VERSION ""

NS_ :

BS_:
BU_: XXX

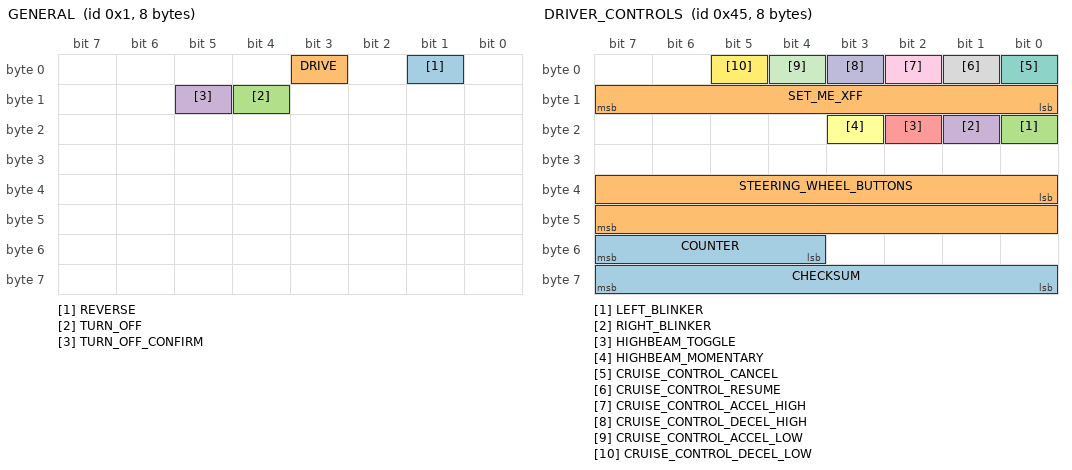
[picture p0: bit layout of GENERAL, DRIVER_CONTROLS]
BO_ 1 GENERAL: 8 XXX
   SG_ REVERSE : 1|1@1+ (1,0) [0|15] "" XXX
   SG_ DRIVE : 3|1@1+ (1,0) [0|15] "" XXX
   SG_ TURN_OFF : 12|1@1+ (1,0) [0|15] "" XXX
   SG_ TURN_OFF_CONFIRM : 13|1@1+ (1,0) [0|15] "" XXX

BO_ 69 DRIVER_CONTROLS: 8 XXX
   SG_ COUNTER : 55|4@0+ (1,0) [0|15] "" XXX
   SG_ STEERING_WHEEL_BUTTONS : 32|16@1+ (1,0) [0|255] "4 directional, 2 volume control & 2 phone buttons" XXX
   SG_ LEFT_BLINKER : 16|1@0+ (1,0) [0|1] "" XXX
   SG_ RIGHT_BLINKER : 17|1@0+ (1,0) [0|1] "" XXX
   SG_ HIGHBEAM_TOGGLE : 18|1@0+ (1,0) [0|1] "" XXX
   SG_ HIGHBEAM_MOMENTARY : 19|1@0+ (1,0) [0|1] "" XXX
   SG_ CRUISE_CONTROL_CANCEL : 0|1@0+ (1,0) [0|1] "" XXX
   SG_ CRUISE_CONTROL_RESUME : 1|1@0+ (1,0) [0|1] "" XXX
   SG_ CRUISE_CONTROL_ACCEL_HIGH : 2|1@0+ (1,0) [0|1] "" XXX
   SG_ CRUISE_CONTROL_DECEL_HIGH : 3|1@0+ (1,0) [0|1] "" XXX
   SG_ CRUISE_CONTROL_ACCEL_LOW : 4|1@0+ (1,0) [0|1] "" XXX
   SG_ CRUISE_CONTROL_DECEL_LOW : 5|1@0+ (1,0) [0|1] "" XXX
   SG_ CHECKSUM : 63|8@0+ (1,0) [0|255] "" XXX
   SG_ SET_ME_XFF : 15|8@0+ (1,0) [0|255] "" XXX

BO_ 115 GEAR_PACKET: 8 XXX
   SG_ GEAR : 0|4@1+ (1,0) [0|15] "" XXX

BO_ 261 GAS_PEDAL: 8 XXX
   SG_ ENGINE_RPM : 6|15@0+ (1,0) [0|255] "rev per X" XXX
   SG_ KICK_DOWN : 7|1@0+ (1,0) [0|1] "" XXX
   SG_ COMBINED_GAS : 32|8@0+ (1,0) [0|255] "" XXX
   SG_ GAS_PEDAL : 40|8@0+ (1,0) [0|255] "" XXX
   SG_ COUNTER : 55|4@0+ (1,0) [0|15] "" XXX
   SG_ CHECKSUM : 63|8@0+ (1,0) [0|255] "" XXX

BO_ 415 UNKNOWN_SPEEDS: 8 XXX
   SG_ WHEEL_SPEED_FL : 2|11@0+ (0.0375,0) [0|255] "mph" XXX

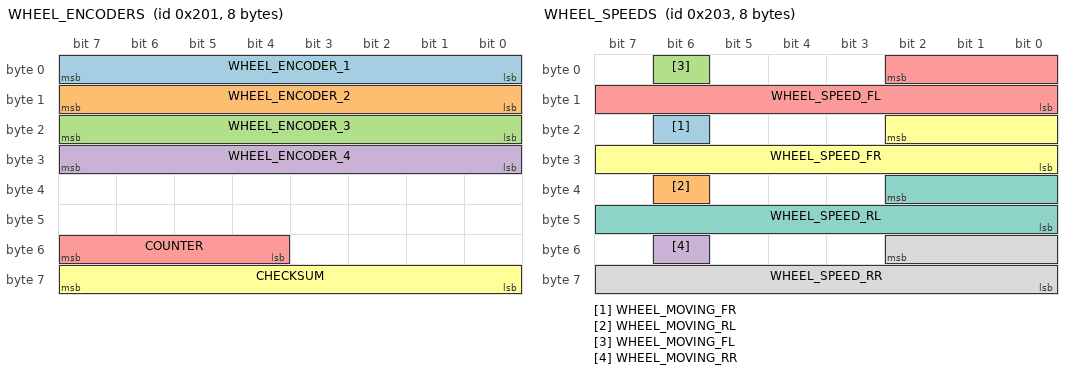
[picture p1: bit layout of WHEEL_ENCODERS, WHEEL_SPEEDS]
BO_ 513 WHEEL_ENCODERS: 8 XXX
   SG_ WHEEL_ENCODER_1 : 7|8@0+ (1,0) [0|255] "" XXX
   SG_ WHEEL_ENCODER_2 : 15|8@0+ (1,0) [0|255] "" XXX
   SG_ WHEEL_ENCODER_3 : 23|8@0+ (1,0) [0|255] "" XXX
   SG_ WHEEL_ENCODER_4 : 31|8@0+ (1,0) [0|255] "" XXX
   SG_ COUNTER : 55|4@0+ (1,0) [0|15] "" XXX
   SG_ CHECKSUM : 56|8@1+ (1,0) [0|255] "" XXX

BO_ 515 WHEEL_SPEEDS: 8 XXX
   SG_ WHEEL_MOVING_FR : 22|1@1+ (1,0) [0|15] "" XXX
   SG_ WHEEL_MOVING_RL : 38|1@0+ (1,0) [0|1] "" XXX
   SG_ WHEEL_MOVING_FL : 6|1@0+ (1,0) [0|1] "" XXX
   SG_ WHEEL_MOVING_RR : 54|1@0+ (1,0) [0|1] "" XXX
   SG_ WHEEL_SPEED_FL : 2|11@0+ (0.0375,0) [0|255] "mph" XXX
   SG_ WHEEL_SPEED_FR : 18|11@0+ (0.0375,0) [0|255] "mph" XXX
   SG_ WHEEL_SPEED_RL : 34|11@0+ (0.0375,0) [0|255] "mph" XXX
   SG_ WHEEL_SPEED_RR : 50|11@0+ (0.0375,0) [0|255] "mph" XXX

BO_ 517 AUX_BAT_VOLTAGE: 8 XXX
   SG_ BAT_12V : 8|8@1+ (0.1,0) [0|255] "V" XXX

BO_ 581 IGNITION: 8 XXX
   SG_ STEERING_WHEEL : 1|15@0- (0.01,0) [-5000|5000] "x" XXX

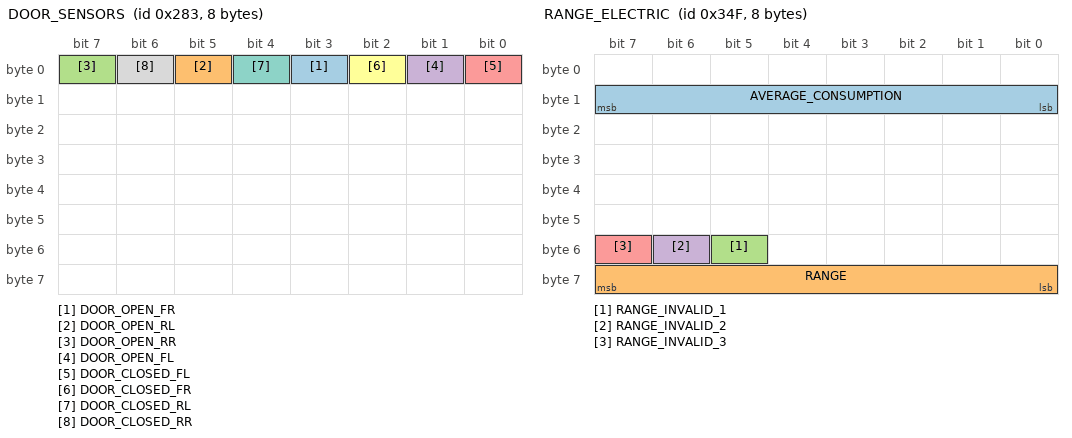
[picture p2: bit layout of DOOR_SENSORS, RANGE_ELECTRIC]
BO_ 643 DOOR_SENSORS: 8 XXX
   SG_ DOOR_OPEN_FR : 3|1@0+ (1,0) [0|1] "" XXX
   SG_ DOOR_OPEN_RL : 5|1@0+ (1,0) [0|1] "" XXX
   SG_ DOOR_OPEN_RR : 7|1@0+ (1,0) [0|1] "" XXX
   SG_ DOOR_OPEN_FL : 1|1@0+ (1,0) [0|1] "" XXX
   SG_ DOOR_CLOSED_FL : 0|1@0+ (1,0) [0|1] "" XXX
   SG_ DOOR_CLOSED_FR : 2|1@0+ (1,0) [0|1] "" XXX
   SG_ DOOR_CLOSED_RL : 4|1@0+ (1,0) [0|1] "" XXX
   SG_ DOOR_CLOSED_RR : 6|1@0+ (1,0) [0|1] "" XXX

BO_ 829 POWER: 8 XXX
   SG_ POWER_CURRENT : 32|8@1+ (1,-100) [0|255] "kW" XXX

BO_ 847 RANGE_ELECTRIC: 8 XXX
   SG_ AVERAGE_CONSUMPTION : 8|8@1+ (1,0.5) [0|255] "kwhpm" XXX
   SG_ RANGE : 56|8@1+ (1,0) [0|1023] "km" XXX
   SG_ RANGE_INVALID_1 : 53|1@1+ (1,0) [0|1] "" XXX
   SG_ RANGE_INVALID_2 : 54|1@1+ (1,0) [0|1] "" XXX
   SG_ RANGE_INVALID_3 : 55|1@1+ (1,0) [0|1] "" XXX

BO_ 846 TRIP: 8 XXX
   SG_ DAILY_TRIP : 0|16@1+ (0.5,0) [0|200] "%" XXX
   SG_ DISTANCE_SINCE_X : 0|16@1+ (0.5,0) [0|200] "%" XXX

BO_ 885 SEATBELT_SENSORS: 8 XXX
   SG_ SEATBELT_DRIVER_OPEN : 16|1@0+ (1,0) [0|1] "" XXX
   SG_ SEATBELT_PASSENGER_OPEN : 18|1@0+ (1,0) [0|1] "" XXX

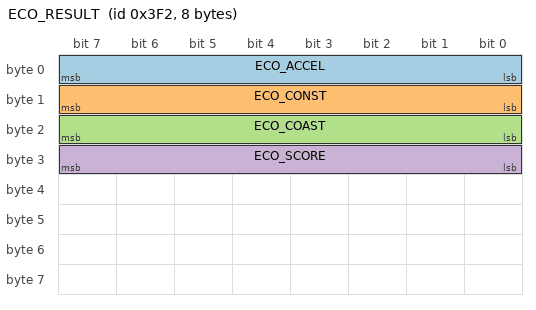
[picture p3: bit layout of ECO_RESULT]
BO_ 1010 ECO_RESULT: 8 XXX
   SG_ ECO_ACCEL : 0|8@1+ (0.5,0) [0|200] "%" XXX
   SG_ ECO_CONST : 8|8@1+ (0.5,0) [0|200] "%" XXX
   SG_ ECO_COAST : 16|8@1+ (0.5,0) [0|200] "%" XXX
   SG_ ECO_SCORE : 24|8@1+ (0.5,0) [0|200] "%" XXX

BA_DEF_ BO_ "GenMsgBackgroundColor" STRING ;
BA_DEF_ BO_ "GenMsgForegroundColor" STRING ;
BA_DEF_DEF_ "GenMsgBackgroundColor" "#ffffff";
BA_DEF_DEF_ "GenMsgForegroundColor" "#000000";
CM_ SG_ 3 STEER_DIRECTION "0 = left, 1 = right";
CM_ SG_ 5 BRAKE_POSITION "computer and driver";
CM_ SG_ 5 BRAKE_PRESSED "computer and driver";
CM_ SG_ 261 GAS_PEDAL "user gas input";
CM_ SG_ 261 COMBINED_GAS "computer and driver gas";
CM_ SG_ 847 RANGE "Range_remaining";
CM_ SG_ 847 RANGE_VALID_1 "Could be sign bit too";
CM_ SG_ 847 RANGE_VALID_2 "Could be part of MS end of range";
CM_ SG_ 847 RANGE_VALID_3 "Could be part of MS end of range";
CM_ SG_ 515 WHEEL_SPEED_FL "kmh scale 0.0603504"
CM_ SG_ 515 WHEEL_SPEED_FR "mph scale 0.0375"
CM_ SG_ 515 FLAP_OPEN "Just guessing"
CM_ SG_ 515 AVERAGE_CONSUMPTION "unit is kWh per Mile"
